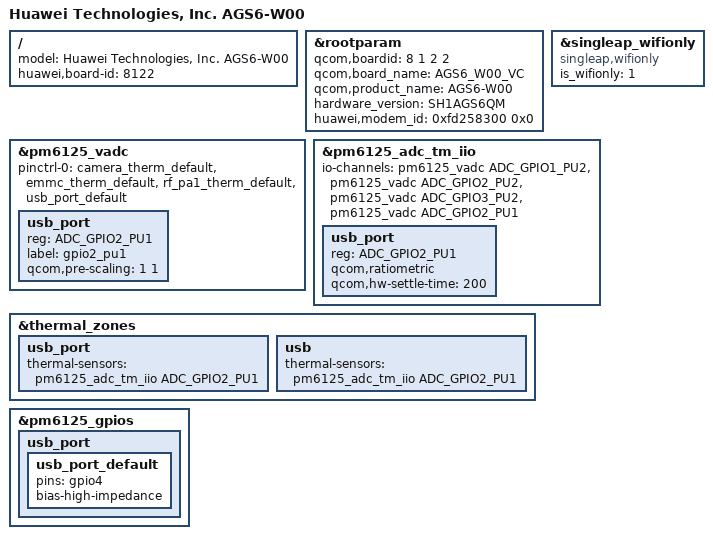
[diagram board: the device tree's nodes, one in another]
/dts-v1/;
/plugin/;

#include "../common/common.dtsi"

/ {
    model = "Huawei Technologies, Inc. AGS6-W00";
    huawei,board-id = <8122>;
};

&rootparam {
    /* auto_key_info @ name: boardid type: uint32 default: 0 */
    qcom,boardid = <8 1 2 2>;
    qcom,board_name = "AGS6_W00_VC";
    qcom,product_name = "AGS6-W00";
    hardware_version = "SH1AGS6QM";
    huawei,modem_id = <0xfd258300 0x0>;
};

&singleap_wifionly {
        compatible = "singleap,wifionly";
        is_wifionly = "1";
        status = "ok";
};

&pm6125_vadc {
	pinctrl-0 = <&camera_therm_default &emmc_therm_default &rf_pa1_therm_default &usb_port_default>;

	usb_port {
		reg = <ADC_GPIO2_PU1>;
		label = "gpio2_pu1";
		qcom,pre-scaling = <1 1>;
	};
};

&pm6125_adc_tm_iio {
	io-channels = <&pm6125_vadc ADC_GPIO1_PU2>,
			<&pm6125_vadc ADC_GPIO2_PU2>,
			<&pm6125_vadc ADC_GPIO3_PU2>,
			<&pm6125_vadc ADC_GPIO2_PU1>;

	usb_port {
		reg = <ADC_GPIO2_PU1>;
		qcom,ratiometric;
		qcom,hw-settle-time = <200>;
	};
};

&thermal_zones {
	usb_port {
		thermal-sensors = <&pm6125_adc_tm_iio ADC_GPIO2_PU1>;
	};
	usb {
		thermal-sensors = <&pm6125_adc_tm_iio ADC_GPIO2_PU1>;
	};
};

&pm6125_gpios {
	usb_port {
		usb_port_default: usb_port_default {
			pins = "gpio4";
			bias-high-impedance;
		};
	};
};
